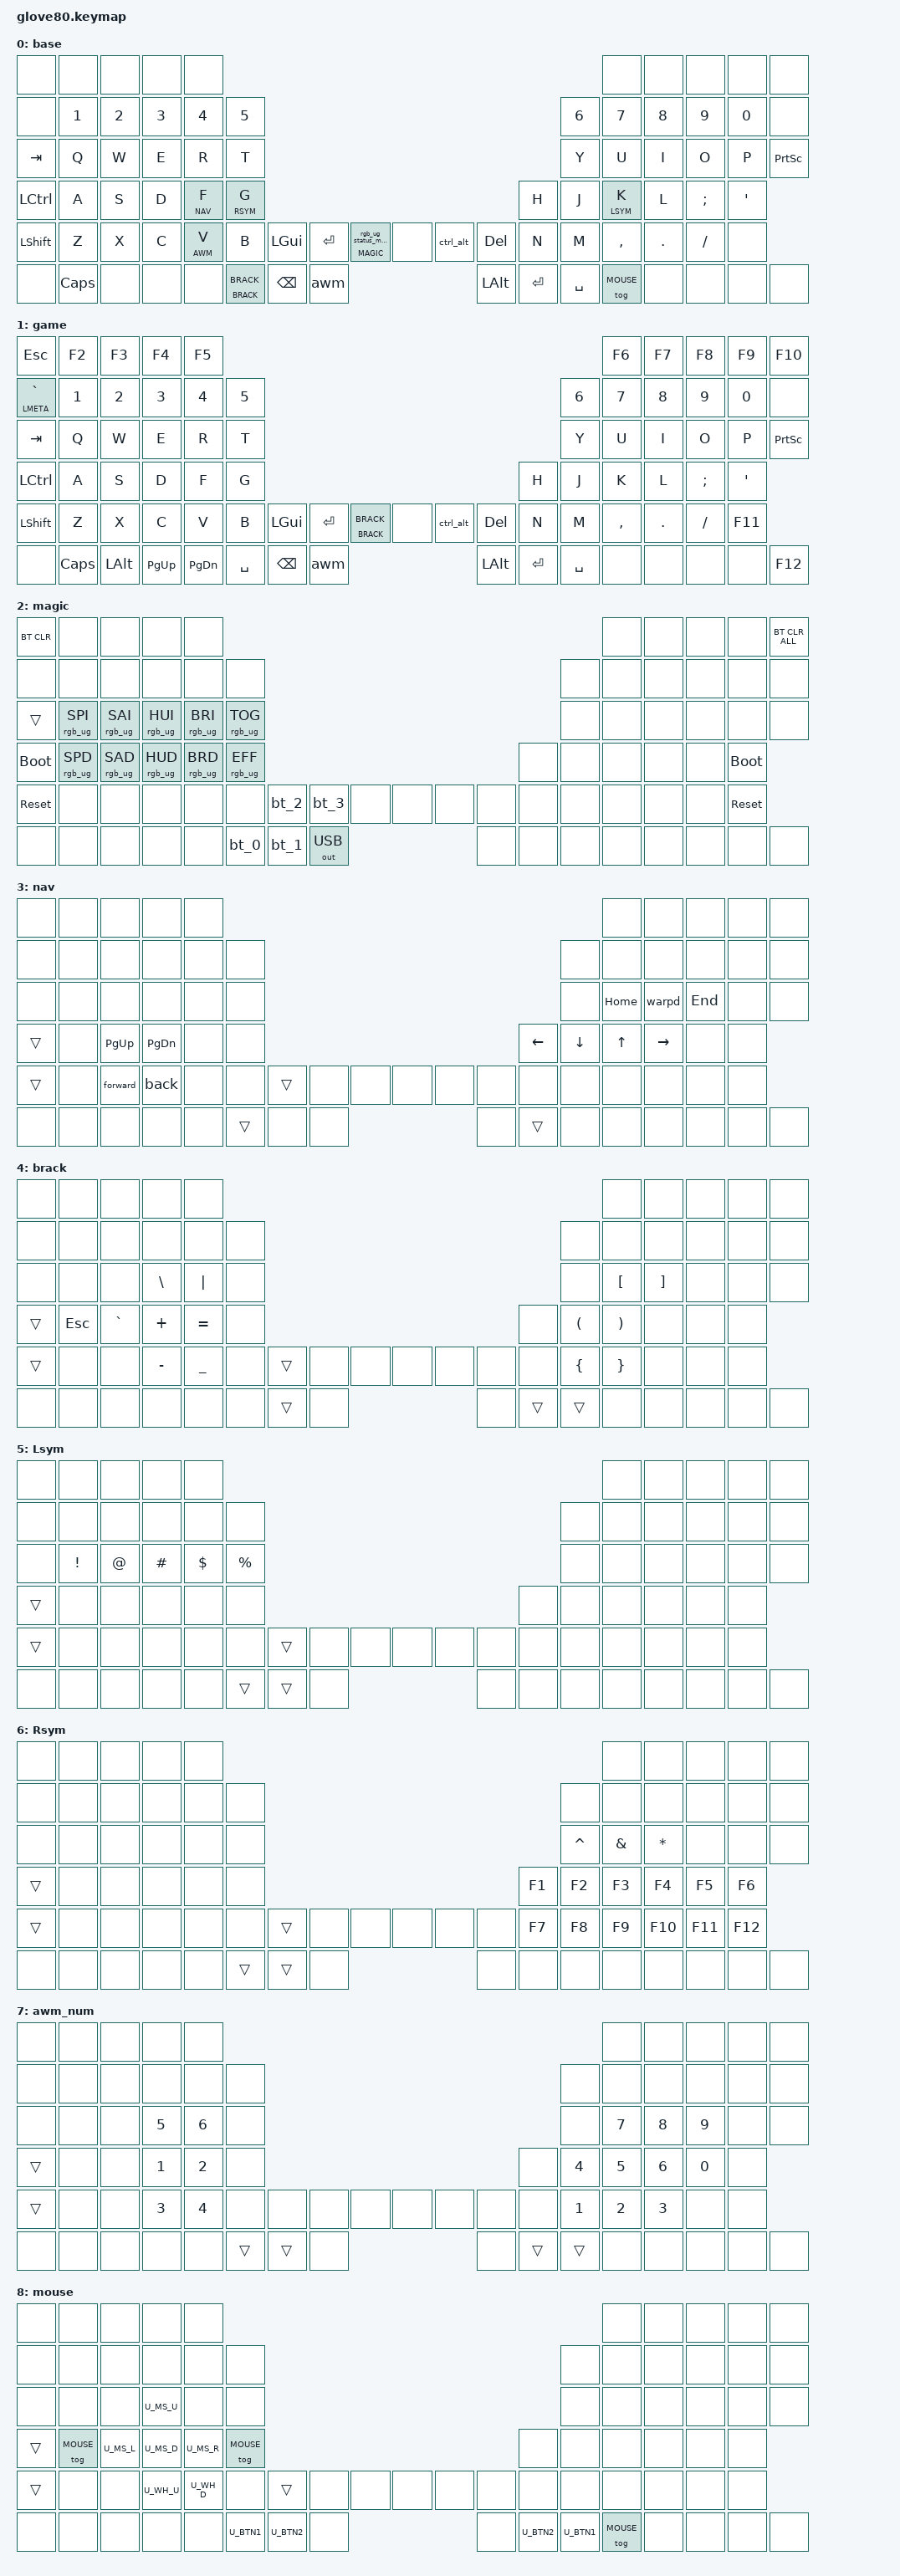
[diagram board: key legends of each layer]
// THIS FILE WAS GENERATED BY GLOVE80 LAYOUT EDITOR
// glove80 tenting leg lengths: top/bottom=15mm, mid=22mm

#include <behaviors.dtsi>

// Include all behaviour includes needed by system behaviors/macros
// Include behaviour includes needed by key binds - automatically generated

#include <dt-bindings/zmk/keys.h>
#include <dt-bindings/zmk/bt.h>
#include <dt-bindings/zmk/rgb.h>
#include <dt-bindings/zmk/outputs.h>
#include "./mouse.dtsi"

// Layer definitions are required to be capitalized.
// Layers can only access other layers that appear later in the stack, ie layer 7 cannot access layer 0.
#define BASE    0
#define GAME    1
#define MAGIC   2
#define NAV     3
#define BRACK   4
#define LSYM    5
#define RSYM    6
#define AWM     7
#define MOUSE   8

/* 
Key positions
 0  1  2  3  4                              5  6  7  8  9
10 11 12 13 14 15                       16 17 18 19 20 21
22 23 24 25 26 27                       28 29 30 31 32 33
34 35 36 37 38 39                       40 41 42 43 44 45
46 47 48 49 50 51 \52 53 54\ /55 56 57/ 58 59 60 61 62 63
64 65 66 67 68    \69 70 71\ /72 73 74/    75 76 77 78 79 
*/

#define COMBO(NAME, BINDINGS, KEYPOS, LAYERS) \
  combo_##NAME { \
    timeout-ms = <50>; \
    global-quick-tap-ms = <100>; \
    bindings = <BINDINGS>; \
    key-positions = <KEYPOS>; \
    layers = <LAYERS>; \
  };

&sl {
    release-after-ms = <500>;
};

/ {
    /* Glove80 system behavior, combos, macros */

    behaviors {

        mo_sl: behavior_mo_sl {
            compatible = "zmk,behavior-hold-tap";
            label = "mo_sl";
            #binding-cells = <2>;
            tapping-term-ms = <280>;
            flavor = "balanced";
            quick-tap-ms = <175>;
            global-quick-tap-ms = <50>;
            bindings =
                <&mo>,
                <&sl>;
        };
        hl: hl {
            compatible = "zmk,behavior-hold-tap";
            label = "hl";
            #binding-cells = <2>;
            tapping-term-ms = <280>;
            flavor = "balanced";
            quick-tap-ms = <175>;
            global-quick-tap-ms = <50>;
            hold-trigger-key-positions = <9 29 30 40 41 42 43 28 31 36 37>;
            hold-trigger-on-release;
            bindings =
                <&mo>,
                <&kp>;
        };
        hr: hr {
            compatible = "zmk,behavior-hold-tap";
            label = "hr";
            #binding-cells = <2>;
            tapping-term-ms = <280>;
            flavor = "balanced";
            quick-tap-ms = <175>;
            global-quick-tap-ms = <50>;
            hold-trigger-key-positions = <23 24 25 26 27 37 38 49 50>;
            hold-trigger-on-release;
            bindings =
                <&mo>,
                <&kp>;
        };
    };

// COMBO(NAME, BINDINGS, KEYPOS, ACTIVE IN LAYERS)
    combos {
        compatible = "zmk,combos";

        COMBO(game, &tog GAME, 24 25 26, BASE GAME)
        COMBO(mouse, &tog MOUSE, 36 37 38, BASE MOUSE)
        //COMBO(tab, &kp TAB, 36 37, 0 1)

    };

    macros {
        awm: awm {
            label = "awm";
            compatible = "zmk,behavior-macro";
            #binding-cells = <0>;
            wait-ms = <0>;
            bindings =
                <&macro_press>,
                <&mo 7 &kp LGUI>, //
                <&macro_pause_for_release>,
                <&macro_release>,
                <&mo 7 &kp LGUI>;
        };

        warpd: warpd {
            label = "warpd";
            compatible = "zmk,behavior-macro";
            #binding-cells = <0>;
            wait-ms = <0>;
            bindings =
                <&macro_press>,
                <&kp LGUI &kp LALT>,
                <&macro_tap>,
                <&kp A>,
                <&macro_release>,
                <&kp LGUI &kp LALT>;
        };

        ctrl_alt: ctrl_alt {
            label = "ctrl_alt";
            compatible = "zmk,behavior-macro";
            #binding-cells = <0>;
            wait-ms = <0>;
            bindings =
                <&macro_press>,
                <&kp LCTRL &kp LALT>,
                <&macro_pause_for_release>,
                <&macro_release>,
                <&kp LCTRL &kp LALT>;
        };

        back: back {
            label = "back";
            compatible = "zmk,behavior-macro";
            #binding-cells = <0>;
            wait-ms = <0>;
            bindings =
                <&macro_press>,
                <&kp LALT>,
                <&macro_tap>,
                <&kp LEFT>,
                <&macro_release>,
                <&kp LALT>;
        };

        forward: forward {
            label = "forward";
            compatible = "zmk,behavior-macro";
            #binding-cells = <0>;
            wait-ms = <0>;
            bindings =
                <&macro_press>,
                <&kp LALT>,
                <&macro_tap>,
                <&kp RIGHT>,
                <&macro_release>,
                <&kp LALT>;
        };

        rgb_ug_status_macro: rgb_ug_status_macro {
            label = "RGB_UG_STATUS";
            compatible = "zmk,behavior-macro";
            #binding-cells = <0>;
            bindings = <&rgb_ug RGB_STATUS>;
        };

        bt_0: bt_0 {
            label = "BT_0";
            compatible = "zmk,behavior-macro";
            #binding-cells = <0>;
            bindings = <&out OUT_BLE &bt BT_SEL 0>;
        };

        bt_1: bt_1 {
            label = "BT_1";
            compatible = "zmk,behavior-macro";
            #binding-cells = <0>;
            bindings = <&out OUT_BLE &bt BT_SEL 1>;
        };

        bt_2: bt_2 {
            label = "BT_2";
            compatible = "zmk,behavior-macro";
            #binding-cells = <0>;
            bindings = <&out OUT_BLE &bt BT_SEL 2>;
        };

        bt_3: bt_3 {
            label = "BT_3";
            compatible = "zmk,behavior-macro";
            #binding-cells = <0>;
            bindings = <&out OUT_BLE &bt BT_SEL 3>;
        };
    };

    magic: magic_hold_tap {
        compatible = "zmk,behavior-hold-tap";
        label = "MAGIC_HOLD_TAP";
        #binding-cells = <2>;
        flavor = "tap-preferred";
        tapping-term-ms = <200>;
        bindings =
            <&mo>,
            <&rgb_ug_status_macro>;
    };

    // Custom Defined Behaviors 
    // Automatically generated keymap 

    keymap {
        compatible = "zmk,keymap";

        base {
            bindings = <
         &none  &none    &none     &none     &none                                                                                                  &none     &none   &none    &none  &none
&none  &kp N1    &kp N2     &kp N3     &kp N4   &kp N5                                                                                &kp N6  &kp N7     &kp N8   &kp N9    &kp N0    &none
        &kp TAB   &kp Q     &kp W      &kp E      &kp R    &kp T                                                                                  &kp Y   &kp U      &kp I    &kp O     &kp P    &kp PRINTSCREEN
      &kp LCTRL   &kp A     &kp S      &kp D    &hl NAV F  &hl RSYM G                                                                          &kp H   &kp J    &hr LSYM K    &kp L  &kp SEMI  &kp SQT
      &kp LSHFT   &kp Z     &kp X      &kp C      &hl AWM V    &kp B    &kp LGUI      &kp ENTER  &magic MAGIC 0  &none &ctrl_alt  &kp DELETE   &kp N   &kp M  &kp COMMA  &kp DOT  &kp FSLH  &none
          &none &kp CAPS  &none  &none &none          &mo_sl BRACK BRACK  &kp BACKSPACE        &awm            &kp LALT  &kp ENTER   &kp SPACE           &tog MOUSE   &none    &none     &none  &none
            >;
        };

        game {
            bindings = <
         &kp ESC  &kp F2    &kp F3     &kp F4     &kp F5                                                                                                 &kp F6     &kp F7   &kp F8    &kp F9    &kp F10
&mt LMETA GRAVE  &kp N1    &kp N2     &kp N3     &kp N4   &kp N5                                                                                &kp N6  &kp N7     &kp N8   &kp N9    &kp N0    &none
        &kp TAB   &kp Q     &kp W      &kp E      &kp R    &kp T                                                                                 &kp Y   &kp U      &kp I    &kp O     &kp P    &kp PRINTSCREEN
      &kp LCTRL   &kp A     &kp S      &kp D    &kp F  &kp G                                                                                 &kp H   &kp J    &kp K    &kp L  &kp SEMI  &kp SQT
      &kp LSHFT   &kp Z     &kp X      &kp C      &kp V    &kp B   &kp LGUI      &kp ENTER  &mo_sl BRACK BRACK  &none  &ctrl_alt  &kp DELETE   &kp N   &kp M  &kp COMMA  &kp DOT  &kp FSLH  &kp F11
          &none &kp CAPS &kp LALT  &kp PG_UP  &kp PG_DN           &kp SPACE  &kp BACKSPACE        &awm            &kp LALT  &kp ENTER   &kp SPACE           &none   &none   &none     &none  &kp F12
            >;
        };

        magic {
            bindings = <
 &bt BT_CLR            &none            &none            &none            &none                                                                           &none  &none  &none  &none  &bt BT_CLR_ALL
      &none            &none            &none            &none            &none            &none                                                   &none  &none  &none  &none  &none           &none
     &trans  &rgb_ug RGB_SPI  &rgb_ug RGB_SAI  &rgb_ug RGB_HUI  &rgb_ug RGB_BRI  &rgb_ug RGB_TOG                                                   &none  &none  &none  &none  &none           &none
&bootloader  &rgb_ug RGB_SPD  &rgb_ug RGB_SAD  &rgb_ug RGB_HUD  &rgb_ug RGB_BRD  &rgb_ug RGB_EFF                                                   &none  &none  &none  &none  &none     &bootloader
     &sys_reset            &none            &none            &none            &none            &none  &bt_2  &bt_3         &none  &none  &none  &none  &none  &none  &none  &none  &none          &sys_reset
      &none            &none            &none            &none            &none                   &bt_0  &bt_1  &out OUT_USB  &none  &none  &none         &none  &none  &none  &none           &none
            >;
        };

        nav {
            bindings = <
 &none  &none     &none  &none  &none                                                                 &none   &none      &none  &none  &none
 &none  &none     &none  &none  &none  &none                                                &none     &none   &none      &none  &none  &none
 &none  &none     &none  &none  &none  &none                                                &none  &kp HOME  &warpd    &kp END  &none  &none
&trans  &none     &kp PG_UP  &kp PG_DN  &none  &none                                             &kp LEFT  &kp DOWN  &kp UP  &kp RIGHT  &none  &none
&trans  &none     &forward  &back  &none &none   &trans  &none  &none  &none  &none  &none     &none     &none   &none      &none  &none  &none
 &none  &none     &none  &none  &none         &trans  &none  &none  &none  &trans  &none               &none   &none      &none  &none  &none
            >;
        };

        brack {
            bindings = <
 &none  &none  &none          &none         &none                                                                            &none                  &none  &none  &none  &none
 &none  &none  &none          &none         &none  &none                                               &none                 &none                  &none  &none  &none  &none
 &none  &none  &none  &kp BACKSLASH      &kp PIPE  &none                                               &none      &kp LEFT_BRACKET      &kp RIGHT_BRACKET  &none  &none  &none
&trans  &kp ESC  &kp GRAVE    &kp PLUS  &kp EQUAL  &none                                               &none  &kp LEFT_PARENTHESIS  &kp RIGHT_PARENTHESIS  &none  &none  &none
&trans  &none  &none   &kp MINUS     &kp UNDER  &none  &trans   &none  &none  &none   &none   &none  &none        &kp LEFT_BRACE        &kp RIGHT_BRACE  &none  &none  &none
 &none  &none  &none          &none         &none         &none &trans  &none  &none  &trans  &trans                        &none                  &none  &none  &none  &none
            >;
        };

        Lsym {
            bindings = <
 &none     &none   &none     &none       &none                                                                 &none  &none  &none  &none  &none
 &none     &none   &none     &none       &none        &none                                             &none  &none  &none  &none  &none  &none
 &none  &kp EXCL  &kp AT  &kp HASH  &kp DOLLAR  &kp PERCENT                                             &none  &none  &none  &none  &none  &none
&trans     &none  &none    &none     &none      &none                                           &none  &none  &none  &none  &none  &none
&trans     &none  &none    &none     &none     &none  &trans  &none  &none  &none  &none  &none  &none  &none  &none  &none  &none  &none
 &none     &none   &none     &none       &none               &trans  &trans  &none  &none  &none  &none         &none  &none  &none  &none  &none
            >;
        };

        Rsym {
            bindings = <
 &none  &none  &none  &none  &none                                                                  &none         &none  &none  &none  &none
 &none  &none  &none  &none  &none  &none                                                 &none     &none         &none  &none  &none  &none
 &none  &none  &none  &none  &none  &none                                             &kp CARET  &kp AMPS  &kp ASTERISK  &none  &none  &none
&trans  &none  &none  &none  &none  &none                                                 &kp F1   &kp F2   &kp F3  &kp F4 &kp F5  &kp F6
&trans  &none  &none  &none  &none  &none   &trans  &none  &none  &none  &none  &none      &kp F7 &kp F8 &kp F9 &kp F10 &kp F11 &kp F12
 &none  &none  &none  &none  &none         &trans  &trans  &none  &none  &none  &none                &none         &none  &none  &none  &none
            >;
        };

        awm_num {
            bindings = <
 &none  &none  &none   &none   &none                                                           &none  &none  &none  &none  &none
 &none  &none  &none   &none   &none  &none                                             &none  &none  &none  &none  &none  &none
 &none  &none  &none  &kp N5  &kp N6  &none                                             &none  &kp N7 &kp N8 &kp N9 &none  &none
&trans  &none  &none  &kp N1  &kp N2  &none                                             &none  &kp N4 &kp N5 &kp N6 &kp N0 &none
&trans  &none  &none  &kp N3  &kp N4  &none   &none  &none  &none  &none  &none  &none  &none  &kp N1 &kp N2 &kp N3 &none  &none
 &none  &none  &none   &none   &none         &trans  &trans  &none  &none  &trans  &trans         &none  &none  &none  &none  &none
            >;
        };

        mouse {
            bindings = <
 &none  &none  &none   &none   &none                                                           &none  &none  &none  &none  &none
 &none  &none  &none   &none   &none  &none                                             &none  &none  &none  &none  &none  &none
 &none  &none  &none  U_MS_U  &none &none                                             &none  &none &none &none &none  &none
&trans  &tog MOUSE  U_MS_L  U_MS_D U_MS_R  &tog MOUSE                                             &none  &none &none &none &none &none
&trans  &none  &none  U_WH_U U_WH_D &none   &trans  &none  &none  &none  &none  &none  &none  &none &none &none &none  &none
 &none  &none  &none   &none   &none         U_BTN1  U_BTN2  &none  &none  U_BTN2  U_BTN1         &tog MOUSE  &none  &none  &none  &none
            >;
        };
    };
};
